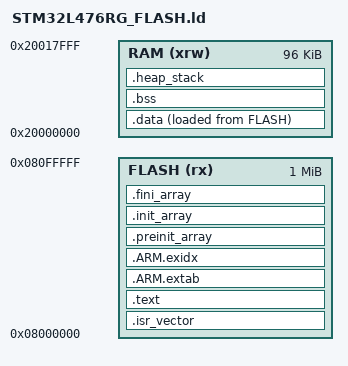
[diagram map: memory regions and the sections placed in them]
/* Standalone firmware: 1 MiB flash and 96 KiB contiguous SRAM1.
 * SRAM2 is intentionally unused. No FreeJoy bootloader required. */
ENTRY(Reset_Handler)
MEMORY {
  FLASH (rx) : ORIGIN = 0x08000000, LENGTH = 1024K
  RAM (xrw) : ORIGIN = 0x20000000, LENGTH = 96K
}
_estack = ORIGIN(RAM) + LENGTH(RAM);
SECTIONS {
  .isr_vector : { . = ALIGN(4); KEEP(*(.isr_vector)) } > FLASH
  .text : {
    *(.text*) *(.rodata*) *(.glue_7*)
    KEEP(*(.init)) KEEP(*(.fini))
    . = ALIGN(4);
  } > FLASH
  .ARM.extab : { *(.ARM.extab*) } > FLASH
  .ARM.exidx : {
    __exidx_start = .; *(.ARM.exidx*) __exidx_end = .;
  } > FLASH
  .preinit_array : {
    __preinit_array_start = .; KEEP(*(.preinit_array*)) __preinit_array_end = .;
  } > FLASH
  .init_array : {
    __init_array_start = .; KEEP(*(SORT(.init_array.*))) KEEP(*(.init_array)) __init_array_end = .;
  } > FLASH
  .fini_array : {
    __fini_array_start = .; KEEP(*(SORT(.fini_array.*))) KEEP(*(.fini_array)) __fini_array_end = .;
  } > FLASH
  _sidata = LOADADDR(.data);
  .data : { . = ALIGN(4); _sdata = .; *(.data*) . = ALIGN(4); _edata = .; } > RAM AT> FLASH
  .bss (NOLOAD) : {
    . = ALIGN(4); _sbss = .; __bss_start__ = .;
    *(.bss*) *(COMMON)
    . = ALIGN(4); _ebss = .; __bss_end__ = .;
  } > RAM
  .heap_stack (NOLOAD) : {
    . = ALIGN(8); end = .; _end = .;
    . += 0x400; . += 0x1000;
  } > RAM
}
